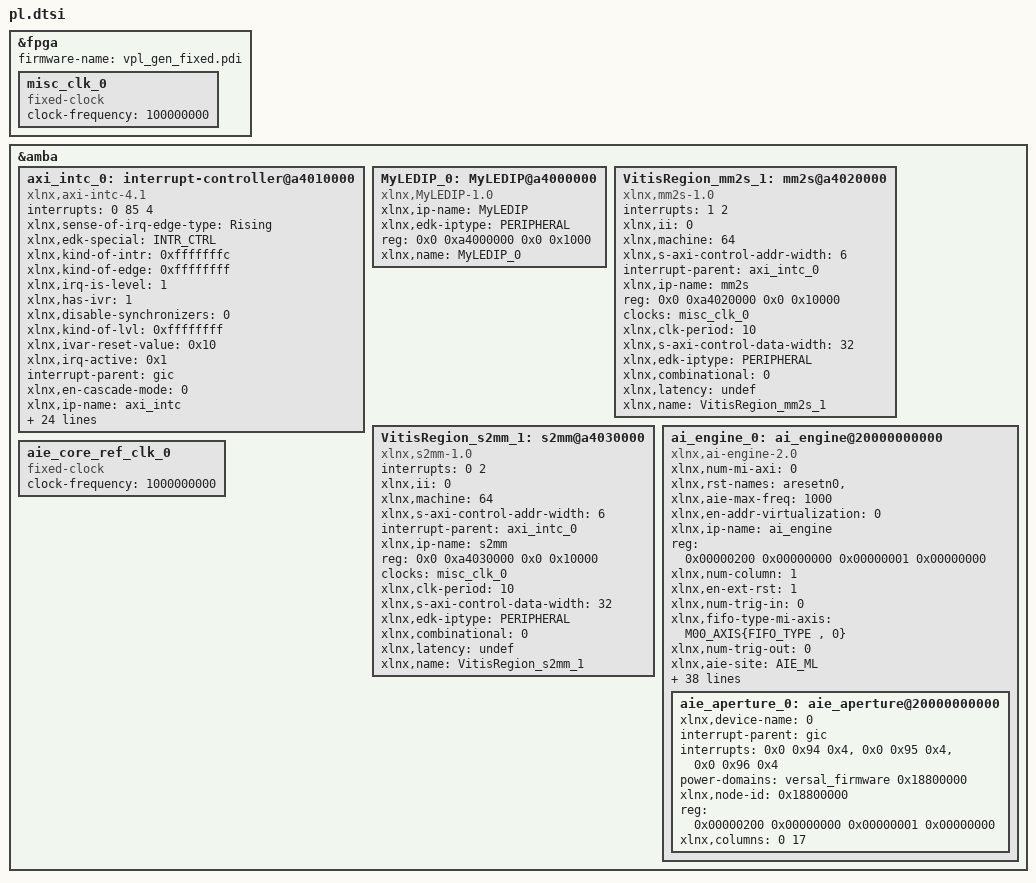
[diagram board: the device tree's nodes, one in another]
/dts-v1/;
/plugin/;
&fpga {
	firmware-name = "vpl_gen_fixed.pdi";
	misc_clk_0: misc_clk_0 {
		compatible = "fixed-clock";
		clock-frequency = <100000000>;
		#clock-cells = <0>;
	};
};

&amba {
	axi_intc_0: interrupt-controller@a4010000 {
		#interrupt-cells = <2>;
		interrupts = < 0 85 4 >;
		xlnx,sense-of-irq-edge-type = "Rising";
		xlnx,edk-special = "INTR_CTRL";
		xlnx,kind-of-intr = <0xfffffffc>;
		xlnx,kind-of-edge = <0xffffffff>;
		xlnx,irq-is-level = <1>;
		xlnx,has-ivr = <1>;
		compatible = "xlnx,axi-intc-4.1" , "xlnx,xps-intc-1.00.a";
		xlnx,disable-synchronizers = <0>;
		xlnx,kind-of-lvl = <0xffffffff>;
		xlnx,ivar-reset-value = <0x10>;
		xlnx,irq-active = <0x1>;
		interrupt-parent = <&gic>;
		xlnx,en-cascade-mode = <0>;
		xlnx,ip-name = "axi_intc";
		xlnx,has-ilr = <0>;
		reg = <0x0 0xa4010000 0x0 0x10000>;
		xlnx,addr-width = <0x20>;
		clocks = <&misc_clk_0>;
		xlnx,s-axi-aclk-freq-mhz = <100>;
		xlnx,num-sw-intr = <0>;
		xlnx,irq-connection = <1>;
		xlnx,num-intr-inputs = <0x20>;
		xlnx,has-sie = <1>;
		xlnx,enable-async = <0>;
		xlnx,has-cie = <1>;
		xlnx,num-sync-ff = <2>;
		xlnx,edk-iptype = "PERIPHERAL";
		xlnx,mb-clk-not-connected = <1>;
		xlnx,has-ipr = <1>;
		xlnx,sense-of-irq-level-type = "Active_High";
		xlnx,cascade-master = <0>;
		xlnx,processor-clk-freq-mhz = <100>;
		xlnx,is-fast = <0x0>;
		clock-names = "s_axi_aclk";
		xlnx,has-fast = <0>;
		xlnx,ivar-rst-val = <0x10>;
		interrupt-controller;
		interrupt-names = "irq";
		xlnx,async-intr = <0xfffffffc>;
		xlnx,name = "axi_intc_0";
	};
	MyLEDIP_0: MyLEDIP@a4000000 {
		compatible = "xlnx,MyLEDIP-1.0";
		xlnx,ip-name = "MyLEDIP";
		xlnx,edk-iptype = "PERIPHERAL";
		reg = <0x0 0xa4000000 0x0 0x1000>;
		xlnx,name = "MyLEDIP_0";
	};
	VitisRegion_mm2s_1: mm2s@a4020000 {
		interrupts = < 1 2 >;
		compatible = "xlnx,mm2s-1.0";
		xlnx,ii = <0>;
		xlnx,machine = <64>;
		xlnx,s-axi-control-addr-width = <6>;
		interrupt-parent = <&axi_intc_0>;
		xlnx,ip-name = "mm2s";
		reg = <0x0 0xa4020000 0x0 0x10000>;
		clocks = <&misc_clk_0>;
		xlnx,clk-period = <10>;
		xlnx,s-axi-control-data-width = <32>;
		xlnx,edk-iptype = "PERIPHERAL";
		clock-names = "ap_clk";
		interrupt-names = "interrupt";
		xlnx,combinational = <0>;
		xlnx,latency = "undef";
		xlnx,name = "VitisRegion_mm2s_1";
	};
	VitisRegion_s2mm_1: s2mm@a4030000 {
		interrupts = < 0 2 >;
		compatible = "xlnx,s2mm-1.0";
		xlnx,ii = <0>;
		xlnx,machine = <64>;
		xlnx,s-axi-control-addr-width = <6>;
		interrupt-parent = <&axi_intc_0>;
		xlnx,ip-name = "s2mm";
		reg = <0x0 0xa4030000 0x0 0x10000>;
		clocks = <&misc_clk_0>;
		xlnx,clk-period = <10>;
		xlnx,s-axi-control-data-width = <32>;
		xlnx,edk-iptype = "PERIPHERAL";
		clock-names = "ap_clk";
		interrupt-names = "interrupt";
		xlnx,combinational = <0>;
		xlnx,latency = "undef";
		xlnx,name = "VitisRegion_s2mm_1";
	};
	ai_engine_0: ai_engine@20000000000 {
		xlnx,num-mi-axi = <0>;
		xlnx,rst-names = "aresetn0,";
		xlnx,aie-max-freq = <1000>;
		xlnx,en-addr-virtualization = <0>;
		xlnx,ip-name = "ai_engine";
		#size-cells = <2>;
		reg = <0x00000200 0x00000000 0x00000001 0x00000000>;
		xlnx,num-column = <1>;
		#address-cells = <2>;
		xlnx,en-ext-rst = <1>;
		xlnx,num-trig-in = <0>;
		xlnx,fifo-type-mi-axis = "M00_AXIS{FIFO_TYPE , 0}";
		xlnx,num-trig-out = <0>;
		xlnx,aie-site = "AIE_ML";
		compatible = "xlnx,ai-engine-2.0" , "xlnx,ai-engine-v2.0";
		xlnx,mi-destid-pins;
		xlnx,fast-pm-write;
		xlnx,num-noc-axis-clks = <0>;
		ranges;
		xlnx,num-si-axis = <1>;
		xlnx,available-nsu = "NOC_NSU128_X1Y6 0x20000000000 NOC_NSU128_X2Y6 0x20002000000 NOC_NSU128_X3Y6 0x20008000000 NOC_NSU128_X4Y6 0x2000C000000 NOC_NSU128_X5Y6 0x2000E000000 NOC_NSU128_X6Y6 0x20014000000";
		xlnx,selected-nsu = <0>;
		xlnx,name-si-axis = "S00_AXIS,";
		xlnx,auto-pipeline-si-axis = "S00_AXIS{AUTO_PIPELINE , 0}";
		xlnx,name = "ai_engine_0";
		xlnx,aie-ref-clk-freqmhz = <0x1fc9f08>;
		xlnx,aie-gen = /bits/ 8 <0x2>;
		clocks = <&misc_clk_0>;
		xlnx,partition-enabled = <0>;
		xlnx,num-clks = <1>;
		xlnx,clk-names = "aclk0,";
		xlnx,edk-iptype = "PERIPHERAL";
		xlnx,fast-dm-write;
		xlnx,nsu-dict = "NOC_NSU128_X1Y6 0x20000000000 NOC_NSU128_X2Y6 0x20002000000 NOC_NSU128_X3Y6 0x20008000000 NOC_NSU128_X4Y6 0x2000C000000 NOC_NSU128_X5Y6 0x2000E000000 NOC_NSU128_X6Y6 0x20014000000";
		clock-names = "aclk0";
		power-domains = <&versal_firmware 0x18800000>;
		xlnx,start-column = <0>;
		xlnx,name-si-axi = "S00_AXI";
		xlnx,core-rows = /bits/ 8 <2 2>;
		xlnx,aie-col-dict = "col00 0x20000000000 col01 0x20002000000 col02 0x20004000000 col03 0x20006000000 col04 0x20008000000 col05 0x2000A000000 col06 0x2000C000000 col07 0x2000E000000 col08 0x20010000000 col09 0x20012000000 col10 0x20014000000 col11 0x20016000000 col12 0x20018000000 col13 0x2001A000000 col14 0x2001C000000 col15 0x2001E000000 col16 0x20020000000";
		xlnx,num-mi-axis = <1>;
		xlnx,fifo-type-si-axis = "S00_AXIS{FIFO_TYPE , 0}";
		xlnx,name-mi-axis = "M00_AXIS,";
		xlnx,mem-rows = /bits/ 8 <1 1>;
		xlnx,num-si-axi = <1>;
		xlnx,auto-pipeline-mi-axis = "M00_AXIS{AUTO_PIPELINE , 0}";
		xlnx,aie-core-ref-ctrl-freqmhz = <1000>;
		xlnx,name-mi-axi = "M00_AXI";
		xlnx,shim-rows = /bits/ 8 <0 1>;
		aie_aperture_0: aie_aperture@20000000000 {
			xlnx,device-name = <0>;
			interrupt-parent = <&gic>;
			interrupts = <0x0 0x94 0x4>, <0x0 0x95 0x4>, <0x0 0x96 0x4>;
			#address-cells = <2>;
			power-domains = <&versal_firmware 0x18800000>;
			xlnx,node-id = <0x18800000>;
			#size-cells = <2>;
			interrupt-names = "interrupt1" , "interrupt2" , "interrupt3";
			reg = <0x00000200 0x00000000 0x00000001 0x00000000>;
			xlnx,columns = < 0 17 >;
		};
	};
	aie_core_ref_clk_0: aie_core_ref_clk_0 {
		compatible = "fixed-clock";
		clock-frequency = <1000000000>;
		#clock-cells = <0>;
	};
};
